# nrf9230_enga_radiocore register map
Vendor: Nordic Semiconductor; Series: nRF92; File version: 1
CPU: CM33 r0p4, little endian, MPU, FPU, 3 interrupt priority bits, 480 interrupts, 4 SAU regions
Registers are 32-bit, read-write, reset 0x0 unless marked. A register's access mark holds for its fields unless they carry their own. Offsets are from the block's base; [hi:lo] are bit positions; 'fields as' and 'values as' point back to an identical list.

## GLOBAL_TBM_NS — Trace buffer monitor 0
Base 0xBF003000
Same registers: GLOBAL_TBM_S 0xBF003000 (alternate view of GLOBAL_TBM_NS)
0x00 TASKS_START wo — Start counter
  [0] TASKS_START
    1=Trigger task
0x04 TASKS_STOP wo — Stop counter, clear counter value
  [0] TASKS_STOP
    1=Trigger task
0x08 TASKS_FLUSH wo — Save current counter value to COUNTSNAPSHOT
  [0] TASKS_FLUSH
    1=Trigger task
0x100 EVENTS_HALFFULL — Counter value equals half-full
  [0] EVENTS_HALFFULL
    0=NotGenerated (Event not generated); 1=Generated (Event generated)
0x104 EVENTS_FULL — Counter value equals full
  [0] EVENTS_FULL
    values as EVENTS_HALFFULL.EVENTS_HALFFULL
0x108 EVENTS_FLUSH — Counter value saved to COUNTSNAPSHOT due to flush
  [0] EVENTS_FLUSH
    values as EVENTS_HALFFULL.EVENTS_HALFFULL
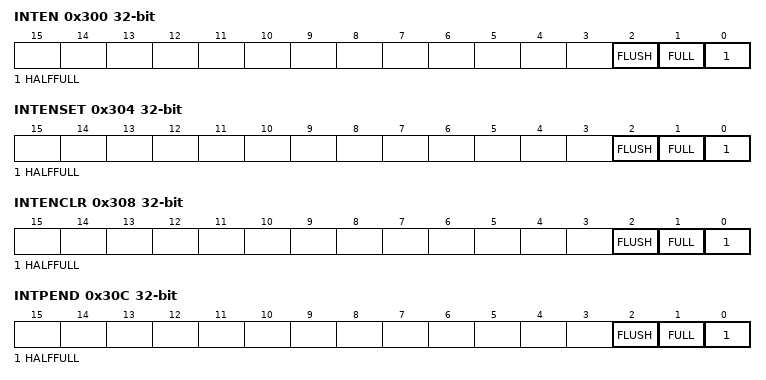
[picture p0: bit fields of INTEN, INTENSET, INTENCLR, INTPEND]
0x300 INTEN — Enable or disable interrupt
  [all] fields
    0=Disabled; 1=Enabled
  [2] FLUSH — Enable or disable interrupt for event FLUSH
  [1] FULL — Enable or disable interrupt for event FULL
  [0] HALFFULL — Enable or disable interrupt for event HALFFULL
0x304 INTENSET — Enable interrupt
  [all] fields
    on read: 0=Disabled (Read: Disabled); 1=Enabled (Read: Enabled) | on write: 1=Set (Enable)
  [2] FLUSH — Write '1' to enable interrupt for event FLUSH
  [1] FULL — Write '1' to enable interrupt for event FULL
  [0] HALFFULL — Write '1' to enable interrupt for event HALFFULL
0x308 INTENCLR — Disable interrupt
  [all] fields
    on read: 0=Disabled (Read: Disabled); 1=Enabled (Read: Enabled) | on write: 1=Clear (Disable)
  [2] FLUSH — Write '1' to disable interrupt for event FLUSH
  [1] FULL — Write '1' to disable interrupt for event FULL
  [0] HALFFULL — Write '1' to disable interrupt for event HALFFULL
0x30C INTPEND ro — Pending interrupts
  [all] fields
    on read: 0=NotPending (Read: Not pending); 1=Pending (Read: Pending)
  [2] FLUSH — Read pending status of interrupt for event FLUSH
  [1] FULL — Read pending status of interrupt for event FULL
  [0] HALFFULL — Read pending status of interrupt for event HALFFULL
0x400 BUFFERSIZE reset 0x400 — System RAM trace buffer total size in bytes
  [12:0] BUFFERSIZE — Must only be configured in STOP mode. Must be programmed to multiple of 16 bytes to make half-buffer size always 64 bit word aligned. Typical minimum BUFFERSIZE value 0x010 i.e. 16 bytes, typical maximum value 0x1000 i.e. 4096 bytes.
    0=Zero (0 bytes); 16=Min (16 bytes); 0x1000=Max (4096 bytes)
0x404 COUNT — Counter current value
  [12:0] COUNT — Counter current value. Only writable when counter is in stopped state. Writing when not in stopped state will generate a bus fault.
0x408 COUNTSNAPSHOT ro — Copy of the current COUNT value
  [12:0] COUNTSNAPSHOT — TASKS_FLUSH will copy the current COUNT value to this register.

## GLOBAL_USBHS_NS — USBHS 0
Base 0x4F086000
Same registers: GLOBAL_USBHS_S 0x5F086000
0x00 TASKS_START wo — Start the USB peripheral.
  [0] TASKS_START
    1=Trigger task
0x100 EVENTS_CORE — Event indicating that interrupt triggered at USBHS core
  [0] EVENTS_CORE
    0=NotGenerated (Event not generated); 1=Generated (Event generated)
0x300 INTEN — Enable or disable interrupt
  [0] CORE — Enable or disable interrupt for event CORE
    0=Disabled; 1=Enabled
0x304 INTENSET — Enable interrupt
  [0] CORE — Write '1' to enable interrupt for event CORE
    on read: 0=Disabled (Read: Disabled); 1=Enabled (Read: Enabled) | on write: 1=Set (Enable)
0x308 INTENCLR — Disable interrupt
  [0] CORE — Write '1' to disable interrupt for event CORE
    on read: 0=Disabled (Read: Disabled); 1=Enabled (Read: Enabled) | on write: 1=Clear (Disable)
0x30C INTPEND ro — Pending interrupts
  [0] CORE — Read pending status of interrupt for event CORE
    on read: 0=NotPending (Read: Not pending); 1=Pending (Read: Pending)
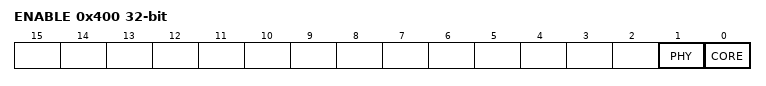
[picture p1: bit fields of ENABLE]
0x400 ENABLE — Enable USB peripheral.
  [1] PHY — Enable USB PHY
    0=Disabled (USB PHY disabled.); 1=Enabled (USB PHY enabled.)
  [0] CORE — Enable USB Controller
    0=Disabled (USB Controller disabled.); 1=Enabled (USB Controller enabled.)

## Notices in the file
Copyright (c) 2010 - 2024, Nordic Semiconductor ASA All rights reserved.
SPDX-License-Identifier: BSD-3-Clause
Redistribution and use in source and binary forms, with or without
modification, are permitted provided that the following conditions are met:
1. Redistributions of source code must retain the above copyright notice, this
list of conditions and the following disclaimer.
2. Redistributions in binary form must reproduce the above copyright
notice, this list of conditions and the following disclaimer in the
documentation and/or other materials provided with the distribution.
3. Neither the name of Nordic Semiconductor ASA nor the names of its
contributors may be used to endorse or promote products derived from this
software without specific prior written permission.
THIS SOFTWARE IS PROVIDED BY THE COPYRIGHT HOLDERS AND CONTRIBUTORS "AS IS"
AND ANY EXPRESS OR IMPLIED WARRANTIES, INCLUDING, BUT NOT LIMITED TO, THE
IMPLIED WARRANTIES OF MERCHANTABILITY, AND FITNESS FOR A PARTICULAR PURPOSE
ARE DISCLAIMED. IN NO EVENT SHALL NORDIC SEMICONDUCTOR ASA OR CONTRIBUTORS BE
LIABLE FOR ANY DIRECT, INDIRECT, INCIDENTAL, SPECIAL, EXEMPLARY, OR
CONSEQUENTIAL DAMAGES (INCLUDING, BUT NOT LIMITED TO, PROCUREMENT OF
SUBSTITUTE GOODS OR SERVICES; LOSS OF USE, DATA, OR PROFITS; OR BUSINESS
INTERRUPTION) HOWEVER CAUSED AND ON ANY THEORY OF LIABILITY, WHETHER IN
CONTRACT, STRICT LIABILITY, OR TORT (INCLUDING NEGLIGENCE OR OTHERWISE)
ARISING IN ANY WAY OUT OF THE USE OF THIS SOFTWARE, EVEN IF ADVISED OF THE
POSSIBILITY OF SUCH DAMAGE.
